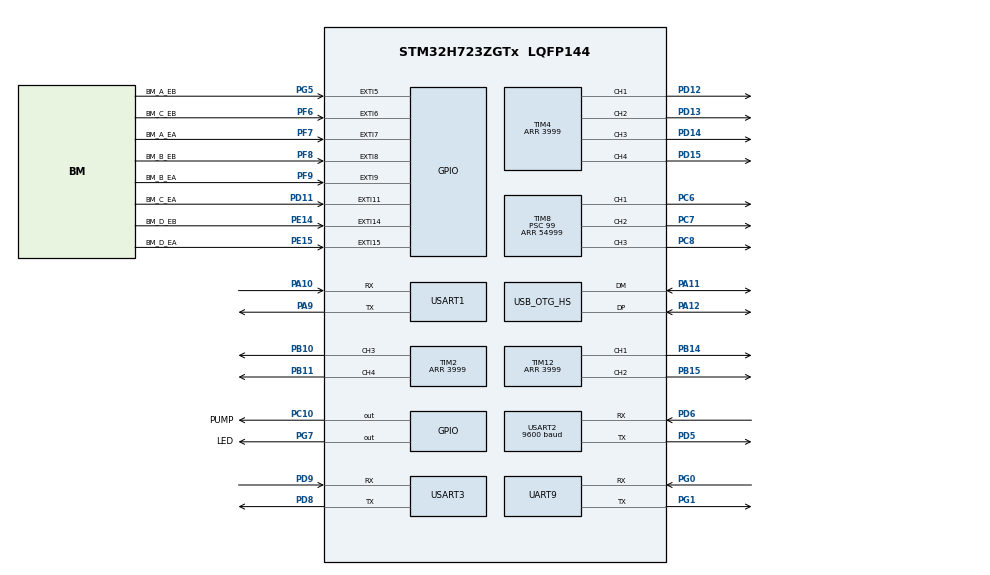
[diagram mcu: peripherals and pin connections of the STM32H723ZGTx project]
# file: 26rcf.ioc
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CORTEX_M7.default_mode_Activation=1
Mcu.Family=STM32H7
Mcu.Name=STM32H723ZGTx
Mcu.Package=LQFP144
NVIC.EXTI15_10_IRQn=true\:0\:0\:false\:false\:true\:true\:true\:true
NVIC.EXTI9_5_IRQn=true\:0\:0\:false\:false\:true\:true\:true\:true
NVIC.OTG_HS_IRQn=true\:0\:0\:false\:false\:true\:false\:true\:true
NVIC.PriorityGroup=NVIC_PRIORITYGROUP_4
NVIC.TIM2_IRQn=true\:0\:0\:false\:false\:true\:true\:true\:true
NVIC.TIM4_IRQn=true\:0\:0\:false\:false\:true\:true\:true\:true
NVIC.TIM8_BRK_TIM12_IRQn=true\:0\:0\:false\:false\:true\:true\:true\:true
NVIC.USART1_IRQn=true\:0\:0\:false\:false\:true\:true\:true\:true
NVIC.USART3_IRQn=true\:0\:0\:false\:false\:true\:true\:true\:true
PA10.Mode=Asynchronous
PA10.Signal=USART1_RX
PA11.Mode=Device_Only_FS
PA11.Signal=USB_OTG_HS_DM
PA12.Mode=Device_Only_FS
PA12.Signal=USB_OTG_HS_DP
PA13(JTMS/SWDIO).Mode=Serial_Wire
PA13(JTMS/SWDIO).Signal=DEBUG_JTMS-SWDIO
PA14(JTCK/SWCLK).Mode=Serial_Wire
PA14(JTCK/SWCLK).Signal=DEBUG_JTCK-SWCLK
PA9.Mode=Asynchronous
PA9.Signal=USART1_TX
PB10.Signal=S_TIM2_CH3
PB11.Signal=S_TIM2_CH4
PB14.Signal=S_TIM12_CH1
PB15.Signal=S_TIM12_CH2
PC10.GPIO_Label=PUMP
PC10.Signal=GPIO_Output
PC6.Signal=S_TIM8_CH1
PC7.Signal=S_TIM8_CH2
PC8.Signal=S_TIM8_CH3
PD11.GPIO_Label=BM_C_EA
PD11.GPIO_ModeDefaultEXTI=GPIO_MODE_IT_RISING_FALLING
PD11.Signal=GPXTI11
PD12.Signal=S_TIM4_CH1
PD13.Signal=S_TIM4_CH2
PD14.Signal=S_TIM4_CH3
PD15.Signal=S_TIM4_CH4
PD5.Mode=Asynchronous
PD5.Signal=USART2_TX
PD6.Mode=Asynchronous
PD6.Signal=USART2_RX
PD8.Mode=Asynchronous
PD8.Signal=USART3_TX
PD9.Mode=Asynchronous
PD9.Signal=USART3_RX
PE14.GPIO_Label=BM_D_EB
PE14.GPIO_ModeDefaultEXTI=GPIO_MODE_IT_RISING_FALLING
PE14.Signal=GPXTI14
PE15.GPIO_Label=BM_D_EA
PE15.GPIO_ModeDefaultEXTI=GPIO_MODE_IT_RISING_FALLING
PE15.Signal=GPXTI15
PF6.GPIO_Label=BM_C_EB
PF6.GPIO_ModeDefaultEXTI=GPIO_MODE_IT_RISING_FALLING
PF6.Signal=GPXTI6
PF7.GPIO_Label=BM_A_EA
PF7.GPIO_ModeDefaultEXTI=GPIO_MODE_IT_RISING_FALLING
PF7.Signal=GPXTI7
PF8.GPIO_Label=BM_B_EB
PF8.GPIO_ModeDefaultEXTI=GPIO_MODE_IT_RISING_FALLING
PF8.Signal=GPXTI8
PF9.GPIO_Label=BM_B_EA
PF9.GPIO_ModeDefaultEXTI=GPIO_MODE_IT_RISING_FALLING
PF9.Signal=GPXTI9
PG0.Mode=Asynchronous
PG0.Signal=UART9_RX
PG1.Mode=Asynchronous
PG1.Signal=UART9_TX
PG5.GPIO_Label=BM_A_EB
PG5.GPIO_ModeDefaultEXTI=GPIO_MODE_IT_RISING_FALLING
PG5.Signal=GPXTI5
PG7.GPIO_Label=LED
PG7.Signal=GPIO_Output
PH0-OSC_IN.Mode=HSE-External-Oscillator
PH0-OSC_IN.Signal=RCC_OSC_IN
PH1-OSC_OUT.Mode=HSE-External-Oscillator
PH1-OSC_OUT.Signal=RCC_OSC_OUT
ProjectManager.HeapSize=0x200
ProjectManager.StackSize=0x400
ProjectManager.TargetToolchain=CMake
RCC.ADCFreq_Value=50390625
RCC.APB1Freq_Value=137500000
RCC.APB2Freq_Value=137500000
RCC.APB3Freq_Value=137500000
RCC.APB4Freq_Value=137500000
RCC.CortexFreq_Value=275000000
RCC.D1PPRE=RCC_APB3_DIV2
RCC.D2PPRE1=RCC_APB1_DIV2
RCC.D2PPRE2=RCC_APB2_DIV2
RCC.D3PPRE=RCC_APB4_DIV2
RCC.DIVM1=5
RCC.DIVM3=5
RCC.DIVN1=110
RCC.DIVN3=48
RCC.DIVQ3=5
RCC.HCLKFreq_Value=275000000
RCC.PLLSourceVirtual=RCC_PLLSOURCE_HSE
RCC.SYSCLKFreq_VALUE=275000000
RCC.SYSCLKSource=RCC_SYSCLKSOURCE_PLLCLK
RCC.USBCLockSelection=RCC_USBCLKSOURCE_PLL3
RCC.USBFreq_Value=48000000
SH.S_TIM12_CH1.0=TIM12_CH1,PWM Generation1 CH1
SH.S_TIM12_CH2.0=TIM12_CH2,PWM Generation2 CH2
SH.S_TIM2_CH3.0=TIM2_CH3,PWM Generation3 CH3
SH.S_TIM2_CH4.0=TIM2_CH4,PWM Generation4 CH4
SH.S_TIM4_CH1.0=TIM4_CH1,PWM Generation1 CH1
SH.S_TIM4_CH2.0=TIM4_CH2,PWM Generation2 CH2
SH.S_TIM4_CH3.0=TIM4_CH3,PWM Generation3 CH3
SH.S_TIM4_CH4.0=TIM4_CH4,PWM Generation4 CH4
SH.S_TIM8_CH1.0=TIM8_CH1,PWM Generation1 CH1
SH.S_TIM8_CH2.0=TIM8_CH2,PWM Generation2 CH2
SH.S_TIM8_CH3.0=TIM8_CH3,PWM Generation3 CH3
TIM12.Channel-PWM\ Generation1\ CH1=TIM_CHANNEL_1
TIM12.Channel-PWM\ Generation2\ CH2=TIM_CHANNEL_2
TIM12.Period=3999
TIM2.Channel-PWM\ Generation3\ CH3=TIM_CHANNEL_3
TIM2.Channel-PWM\ Generation4\ CH4=TIM_CHANNEL_4
TIM2.Period=3999
TIM4.Channel-PWM\ Generation1\ CH1=TIM_CHANNEL_1
TIM4.Channel-PWM\ Generation2\ CH2=TIM_CHANNEL_2
TIM4.Channel-PWM\ Generation3\ CH3=TIM_CHANNEL_3
TIM4.Channel-PWM\ Generation4\ CH4=TIM_CHANNEL_4
TIM4.Period=3999
TIM8.Channel-PWM\ Generation1\ CH1=TIM_CHANNEL_1
TIM8.Channel-PWM\ Generation2\ CH2=TIM_CHANNEL_2
TIM8.Channel-PWM\ Generation3\ CH3=TIM_CHANNEL_3
TIM8.Period=54999
TIM8.Prescaler=99
USART1.VirtualMode-Asynchronous=VM_ASYNC
USART2.BaudRate=9600
USART2.VirtualMode-Asynchronous=VM_ASYNC
USART3.VirtualMode-Asynchronous=VM_ASYNC
USB_DEVICE.CLASS_NAME_HS=CDC
USB_DEVICE.MANUFACTURER_STRING=STM32 Car
USB_DEVICE.VirtualMode=Cdc
USB_DEVICE.VirtualModeHS=Cdc_HS
USB_OTG_HS.VirtualMode-Device_Only_FS=Device_Only_FS
USB_OTG_HS.VirtualMode-OTG/Dual_Role_Device_FS=Device_Role_Device_FS
VP_MEMORYMAP_VS_MEMORYMAP.Mode=CurAppReg
VP_TIM12_VS_ClockSourceINT.Mode=Internal
VP_TIM2_VS_ClockSourceINT.Mode=Internal
VP_TIM4_VS_ClockSourceINT.Mode=Internal
VP_TIM8_VS_ClockSourceINT.Mode=Internal
VP_USB_DEVICE_VS_USB_DEVICE_CDC_HS.Mode=CDC_HS
board=custom

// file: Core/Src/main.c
/* USER CODE BEGIN Header */
/**
  ******************************************************************************
  * @file           : main.c
  * @brief          : Main program body
  ******************************************************************************
  * @attention
  *
  * Copyright (c) 2026 STMicroelectronics.
  * All rights reserved.
  *
  * This software is licensed under terms that can be found in the LICENSE file
  * in the root directory of this software component.
  * If no LICENSE file comes with this software, it is provided AS-IS.
  *
  ******************************************************************************
  */
/* USER CODE END Header */
#include "main.h"
#include "tim.h"
#include "usart.h"
#include "usb_device.h"
#include "gpio.h"

/* USER CODE BEGIN Includes */
#include "user.h"
/* USER CODE END Includes */

void SystemClock_Config(void);
static void MPU_Config(void);

int main(void)
{

  /* MPU Configuration--------------------------------------------------------*/
  MPU_Config();

  /* MCU Configuration--------------------------------------------------------*/

  /* Reset of all peripherals, Initializes the Flash interface and the Systick. */
  HAL_Init();

  /* Configure the system clock */
  SystemClock_Config();

  /* Initialize all configured peripherals */
  MX_GPIO_Init();
  MX_TIM2_Init();
  MX_TIM4_Init();
  MX_TIM8_Init();
  MX_TIM12_Init();
  MX_USART1_UART_Init();
  MX_USART2_UART_Init();
  MX_USART3_UART_Init();
  MX_UART9_Init();
  MX_USB_DEVICE_Init();
  /* USER CODE BEGIN 2 */
  HAL_Delay(100);
  User_Init();

  /* USER CODE END 2 */

  /* Infinite loop */
  while (1)
  {

    /* USER CODE BEGIN 3 */
    User_Update();
  }
  /* USER CODE END 3 */
}

void SystemClock_Config(void)
{
  RCC_OscInitTypeDef RCC_OscInitStruct = {0};
  RCC_ClkInitTypeDef RCC_ClkInitStruct = {0};

  /** Supply configuration update enable
  */
  HAL_PWREx_ConfigSupply(PWR_LDO_SUPPLY);

  /** Configure the main internal regulator output voltage
  */
  __HAL_PWR_VOLTAGESCALING_CONFIG(PWR_REGULATOR_VOLTAGE_SCALE0);

  while(!__HAL_PWR_GET_FLAG(PWR_FLAG_VOSRDY)) {}

  /** Initializes the RCC Oscillators according to the specified parameters
  * in the RCC_OscInitTypeDef structure.
  */
  RCC_OscInitStruct.OscillatorType = RCC_OSCILLATORTYPE_HSE;
  RCC_OscInitStruct.HSEState = RCC_HSE_ON;
  RCC_OscInitStruct.PLL.PLLState = RCC_PLL_ON;
  RCC_OscInitStruct.PLL.PLLSource = RCC_PLLSOURCE_HSE;
  RCC_OscInitStruct.PLL.PLLM = 5;
  RCC_OscInitStruct.PLL.PLLN = 110;
  RCC_OscInitStruct.PLL.PLLP = 2;
  RCC_OscInitStruct.PLL.PLLQ = 2;
  RCC_OscInitStruct.PLL.PLLR = 2;
  RCC_OscInitStruct.PLL.PLLRGE = RCC_PLL1VCIRANGE_2;
  RCC_OscInitStruct.PLL.PLLVCOSEL = RCC_PLL1VCOWIDE;
  RCC_OscInitStruct.PLL.PLLFRACN = 0;
  if (HAL_RCC_OscConfig(&RCC_OscInitStruct) != HAL_OK)
  {
    Error_Handler();
  }

  /** Initializes the CPU, AHB and APB buses clocks
  */
  RCC_ClkInitStruct.ClockType = RCC_CLOCKTYPE_HCLK|RCC_CLOCKTYPE_SYSCLK
                              |RCC_CLOCKTYPE_PCLK1|RCC_CLOCKTYPE_PCLK2
                              |RCC_CLOCKTYPE_D3PCLK1|RCC_CLOCKTYPE_D1PCLK1;
  RCC_ClkInitStruct.SYSCLKSource = RCC_SYSCLKSOURCE_PLLCLK;
  RCC_ClkInitStruct.SYSCLKDivider = RCC_SYSCLK_DIV1;
  RCC_ClkInitStruct.AHBCLKDivider = RCC_HCLK_DIV1;
  RCC_ClkInitStruct.APB3CLKDivider = RCC_APB3_DIV2;
  RCC_ClkInitStruct.APB1CLKDivider = RCC_APB1_DIV2;
  RCC_ClkInitStruct.APB2CLKDivider = RCC_APB2_DIV2;
  RCC_ClkInitStruct.APB4CLKDivider = RCC_APB4_DIV2;

  if (HAL_RCC_ClockConfig(&RCC_ClkInitStruct, FLASH_LATENCY_3) != HAL_OK)
  {
    Error_Handler();
  }
}

 /* MPU Configuration */

void MPU_Config(void)
{
  MPU_Region_InitTypeDef MPU_InitStruct = {0};

  /* Disables the MPU */
  HAL_MPU_Disable();

  /** Initializes and configures the Region and the memory to be protected
  */
  MPU_InitStruct.Enable = MPU_REGION_ENABLE;
  MPU_InitStruct.Number = MPU_REGION_NUMBER0;
  MPU_InitStruct.BaseAddress = 0x0;
  MPU_InitStruct.Size = MPU_REGION_SIZE_4GB;
  MPU_InitStruct.SubRegionDisable = 0x87;
  MPU_InitStruct.TypeExtField = MPU_TEX_LEVEL0;
  MPU_InitStruct.AccessPermission = MPU_REGION_NO_ACCESS;
  MPU_InitStruct.DisableExec = MPU_INSTRUCTION_ACCESS_DISABLE;
  MPU_InitStruct.IsShareable = MPU_ACCESS_SHAREABLE;
  MPU_InitStruct.IsCacheable = MPU_ACCESS_NOT_CACHEABLE;
  MPU_InitStruct.IsBufferable = MPU_ACCESS_NOT_BUFFERABLE;

  HAL_MPU_ConfigRegion(&MPU_InitStruct);
  /* Enables the MPU */
  HAL_MPU_Enable(MPU_PRIVILEGED_DEFAULT);

}

void Error_Handler(void)
{
  __disable_irq();
  while (1)
  {
  }
}
